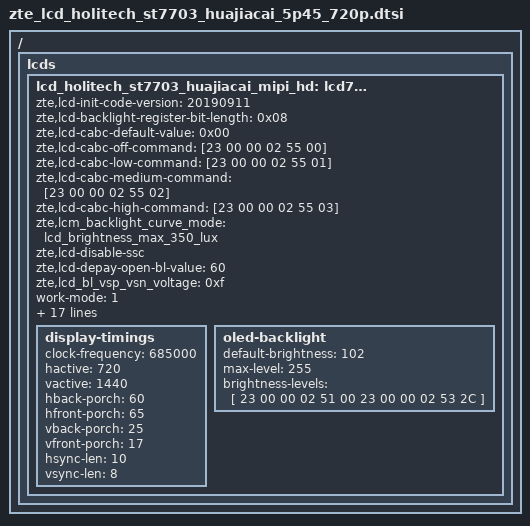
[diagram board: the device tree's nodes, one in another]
/ { lcds {
	lcd_holitech_st7703_huajiacai_mipi_hd: lcd7703@7703 {
		zte,lcd-init-code-version = "20190911";
		zte,lcd-backlight-register-bit-length = <0x08>;
		zte,lcd-cabc-default-value = <0x00>;
		zte,lcd-cabc-off-command = [23 00 00 02 55 00];
		zte,lcd-cabc-low-command = [23 00 00 02 55 01];
		zte,lcd-cabc-medium-command = [23 00 00 02 55 02];
		zte,lcd-cabc-high-command = [23 00 00 02 55 03];
		zte,lcm_backlight_curve_mode = "lcd_brightness_max_350_lux";
		zte,lcd-disable-ssc;
		zte,lcd-depay-open-bl-value = <60>;
		zte,lcd_bl_vsp_vsn_voltage = <0xf>;

		work-mode = <1>;
		bpp = <24>;
		lane-number = <3>;

		need-check-esd = <3>;
		esd-timeout = <2000>;

		fps = <60>;
		width-mm = <62>;
		height-mm = <124>;
		panel-name = "lcd_holitech_st7703_huajiacai_mipi_hd";

		power-on-sequence = <
					88  1  6
					50  1  10
					50  0  12
					50  1  18
					4   1  5
					5   1  15
					>;
		power-off-sequence = <
					5   0   5
					4   0   5
					50  0  20
					>;

		init-data = [
			39 00 00 04 B9 F1 12 83
			39 00 00 1C BA 32 81 05 F9 0E 0E 20 00 00
						00 00 00 00 00 44 25 00 91 0A
						00 00 00 4F D1 00 00 37
			39 00 00 05 B8 76 22 20 03
			39 00 00 04 BF 02 11 00
			39 00 00 0B B3 07 0B 28 28 03 FF 00 00 00
						00
			39 00 00 0A C0 73 73 50 50 A0 00 08 50 00
			39 00 00 02 BC 4f
			39 00 00 02 CC 0B
			39 00 00 02 B4 80
			39 00 00 05 B1 85 00 00 01
			39 00 00 04 B2 F0 12 F0
			39 00 00 0F E3 03 03 03 03 06 06 00 00 00
						00 28 80 00 10
			39 00 00 0D C1 54 00 32 32 77 C1 FF FF EE
						EE 77 77
			39 00 00 03 B5 0E 0E
			39 00 00 03 B6 39 39
			39 00 00 40 E9 C2 10 06 05 A0 80 81 12 31
						23 77 80 80 81 27 18 00 01 02
						00 00 00 00 01 02 00 00 00 F4
						88 64 20 08 88 88 88 88 88 88
						F5 88 75 31 18 88 88 88 88 88
						88 00 00 00 01 00 00 00 00 00
						00 00 00 00
			39 00 00 3E EA 00 1A 00 00 00 00 02 00 00
						00 00 00 81 F8 13 57 58 88 88
						88 88 88 88 80 F8 02 46 48 88
						88 88 88 88 88 23 14 00 00 9C
						00 00 00 00 00 00 00 00 00 00
						00 00 00 00 00 40 80 A1 00 00
						00 00
			39 00 00 04 EF FF FF 01
			39 00 00 23 E0 00 0D 18 27 3D 3F 48 39 07
						0D 0D 10 11 0F 12 11 18 00 0D
						18 27 3D 3F 48 39 07 0D 0D 10
						11 0F 12 11 18
			39 00 00 23 CD 07 80 83 86 85 84 85 82 81
						82 81 80 81 7F 7F 7F 80 7E 7D
						7D 7D 7D 7C 7D 7C 7A 7C 7B 79
						7B 7B 79 7D 77
			39 00 00 22 CE 80 83 86 85 84 85 82 81 82
						81 80 81 7F 7F 7F 80 7E 7D 7D
						7D 7D 7C 7D 7C 7A 7C 7B 79 7B
						7B 79 7D 77
			39 00 00 22 CF 80 83 86 85 84 85 82 81 82
						81 80 81 7F 7F 7F 80 7E 7D 7D
						7D 7D 7C 7D 7C 7A 7C 7B 79 7B
						7B 79 7D 77

			23 00 00 02 c7 b0
			39 00 00 04 c8 10 01 02
			39 00 00 02 51 00
			39 00 00 02 53 2C
			39 00 00 02 55 00
			39 00 00 02 5e 04

			13 78 00 01 11
			13 14 00 01 29
			];
		sleep-in = [
			23 00 00 02 c7 00
			23 00 00 02 53 00
			13 14 00 01 28
			13 96 00 01 10
			];
		sleep-out = [
			13 78 00 01 11
			13 14 00 01 29
			];

		display-timings {
			clock-frequency = <685000>;
			hactive = <720>;
			vactive = <1440>;
			hback-porch = <60>;
			hfront-porch = <65>;
			vback-porch = <25>;
			vfront-porch = <17>;
			hsync-len = <10>;
			vsync-len = <8>;
		};
		oled-backlight {
			default-brightness = <102>;
			max-level = <255>;
			brightness-levels = [
				23 00 00 02 51 00
				23 00 00 02 53 2C
			];
		};
	};
};};

